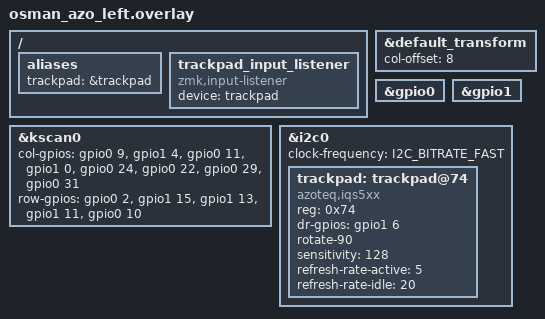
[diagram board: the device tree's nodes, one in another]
#include "osman_azo.dtsi"

/ {
    aliases {
        trackpad = &trackpad;
    };

    // Input listener
    trackpad_input_listener: trackpad_input_listener {
        compatible = "zmk,input-listener";
        device = <&trackpad>;
        status = "okay";
    };
};

&default_transform {
    col-offset = <8>;
};

&kscan0 {
    col-gpios = <&gpio0 9 (GPIO_ACTIVE_HIGH | GPIO_PULL_DOWN)>
              , <&gpio1 4 (GPIO_ACTIVE_HIGH | GPIO_PULL_DOWN)>
              , <&gpio0 11 (GPIO_ACTIVE_HIGH | GPIO_PULL_DOWN)>
              , <&gpio1 0 (GPIO_ACTIVE_HIGH | GPIO_PULL_DOWN)>
              , <&gpio0 24 (GPIO_ACTIVE_HIGH | GPIO_PULL_DOWN)>
              , <&gpio0 22 (GPIO_ACTIVE_HIGH | GPIO_PULL_DOWN)>
              , <&gpio0 29 (GPIO_ACTIVE_HIGH | GPIO_PULL_DOWN)>
              , <&gpio0 31 (GPIO_ACTIVE_HIGH | GPIO_PULL_DOWN)>;
    row-gpios = <&gpio0 2 (GPIO_ACTIVE_HIGH | GPIO_PULL_DOWN)>
              , <&gpio1 15 (GPIO_ACTIVE_HIGH | GPIO_PULL_DOWN)>
              , <&gpio1 13 (GPIO_ACTIVE_HIGH | GPIO_PULL_DOWN)>
              , <&gpio1 11 (GPIO_ACTIVE_HIGH | GPIO_PULL_DOWN)>
              , <&gpio0 10 (GPIO_ACTIVE_HIGH | GPIO_PULL_DOWN)>;
};

// Enable GPIO controllers
&gpio0 {
    status = "okay";
};

&gpio1 {
    status = "okay";
};

&i2c0 {
    status = "okay";
    clock-frequency = <I2C_BITRATE_FAST>;

    trackpad: trackpad@74 {
        compatible = "azoteq,iqs5xx";
        reg = <0x74>;
        dr-gpios = <&gpio1 6 GPIO_ACTIVE_HIGH>;
        status = "okay";
        rotate-90;
        sensitivity = <128>;
        refresh-rate-active = <5>;
        refresh-rate-idle = <20>;
    };
};
